# AT32UC3C1256C device description
Architecture: AVR32_UC3; Family: AVR UC3
Registers are 32-bit, read-write, reset 0x0 unless marked. A register's access mark holds for its fields unless they carry their own. Offsets are from the block's base; [hi:lo] are bit positions; {n}, {i} and the like mark numbered series; 'fields as' and 'values as' point back to an identical list.

## SAU — Secure Access Unit
Instances: SAU 0xfffe2400, SAU_HSB 0x90000000 in hsb
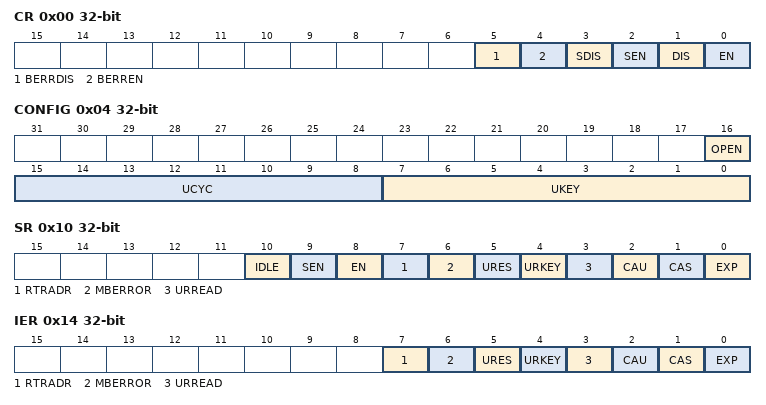
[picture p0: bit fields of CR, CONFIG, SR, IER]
0x00 CR wo reset not defined — Control Register
  [5] BERRDIS — Bus Error Response Disable
  [4] BERREN — Bus Error Response Enable
  [3] SDIS — Setup Mode Disable
  [2] SEN — Setup Mode Enable
  [1] DIS — SAU Disable
  [0] EN — SAU Enable
0x04 CONFIG wo — Configuration Register
  [16] OPEN — Open Mode Enable
  [15:8] UCYC — Unlock number of clock cycles
  [7:0] UKEY — Unlock Key
0x08 CERH — Channel Enable Register High
  [30:0] CERH
0x0C CERL — Channel Enable Register Low
0x10 SR ro — Status Register
  [10] IDLE — SAU Master Interface Idle
  [9] SEN — SAU Setup Mode Enabled
  [8] EN — SAU Enabled
  [7] RTRADR — RTR Address Error
  [6] MBERROR — Master Interface Bus Error
  [5] URES — Unlock Register Error
  [4] URKEY — Unlock Register Key Error
  [3] URREAD — Unlock Register Read
  [2] CAU — Channel Access Unsuccessful
  [1] CAS — Channel Access Successful
  [0] EXP — Channel Unlock Expired
0x14 IER wo reset not defined — Interrupt Enable Register
  [7] RTRADR — Enable Illegal RTR Address Setup Interrupt
  [6] MBERROR — Enable Master Interface Bus Error Interrupt
  [5] URES — Enable Unlock Register Error Interrupt
  [4] URKEY — Enable Unlock Register Key Error Interrupt
  [3] URREAD — Enable Unlock Register Read Interrupt
  [2] CAU — Enable Channel Access Unsuccessful Interrupt
  [1] CAS — Enable Channel Access Successful Interrupt
  [0] EXP — Enable Channel Unlock Expired Interrupt
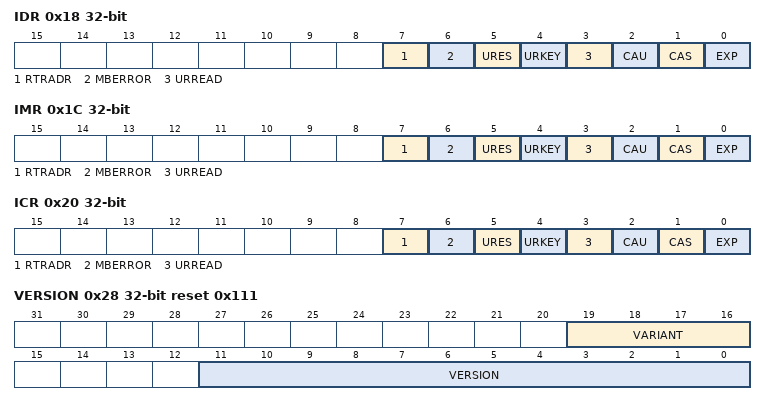
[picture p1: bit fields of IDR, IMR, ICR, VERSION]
0x18 IDR wo reset not defined — Interrupt Disable Register
  [7] RTRADR — Disable Illegal RTR Address Setup Interrupt
  [6] MBERROR — Disable Master Interface Bus Error Interrupt
  [5] URES — Disable Inlock Register Error Interrupt
  [4] URKEY — Disable Unlock Register Key Error Interrupt
  [3] URREAD — Disable Unlock Register Read Interrupt
  [2] CAU — Disable Channel Access Unsuccessful Interrupt
  [1] CAS — Disable Channel Access Successful Interrupt
  [0] EXP — Disable Channel Unlock Expired Interrupt
0x1C IMR ro — Interrupt Mask Register
  [7] RTRADR — Illegal RTR Address Setup Interrupt Mask Bit
  [6] MBERROR — Master Interface Bus Error Interrupt Mask Bit
  [5] URES — Unlock Register Error Interrupt Mask Bit
  [4] URKEY — Unlock Register Key Error Interrupt Mask Bit
  [3] URREAD — Unlock Register Read Interrupt Mask Bit
  [2] CAU — Channel Access Unsuccessful Interrupt Mask Bit
  [1] CAS — Channel Access Successful Interrupt Mask Bit
  [0] EXP — Channel Unlock Expired Interrupt Mask Bit
0x20 ICR wo reset not defined — Interrupt Clear Register
  [7] RTRADR — Clear Illegal RTR Address Setup bit
  [6] MBERROR — Clear Master Interface Bus Error bit
  [5] URES — Clear Unlock Register Error bit
  [4] URKEY — Clear Unlock Register Key Error bit
  [3] URREAD — Clear Unlock Register Read bit
  [2] CAU — Clear Channel Access Unsuccessful bit
  [1] CAS — Clear Channel Access Successful bit
  [0] EXP — Clear Channel Unlock Expired bit
0x24 PARAMETER ro reset 0x10
  [5:0] CHANNELS — SAU Parameters
0x28 VERSION ro reset 0x111
  [19:16] VARIANT — Variant number
  [11:0] VERSION — Version number

## SAU_HSB — Secure Access Unit
{0x0+4i} RTR[{i}] (i=0..62) access not given reset not defined
  [31:0] RTR — Remap Target Address for channel n
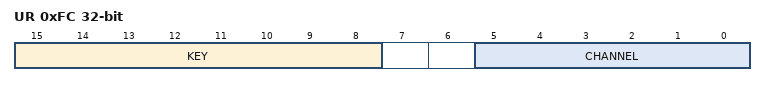
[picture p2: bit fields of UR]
0xFC UR wo reset not defined — Unlock Register
  [15:8] KEY — Unlock Key
  [5:0] CHANNEL — Channel number

## TWIM — Two-wire Master Interface
Instances: TWIM0 0xffff3800, TWIM1 0xffff3c00, TWIM2 0xfffd2c00
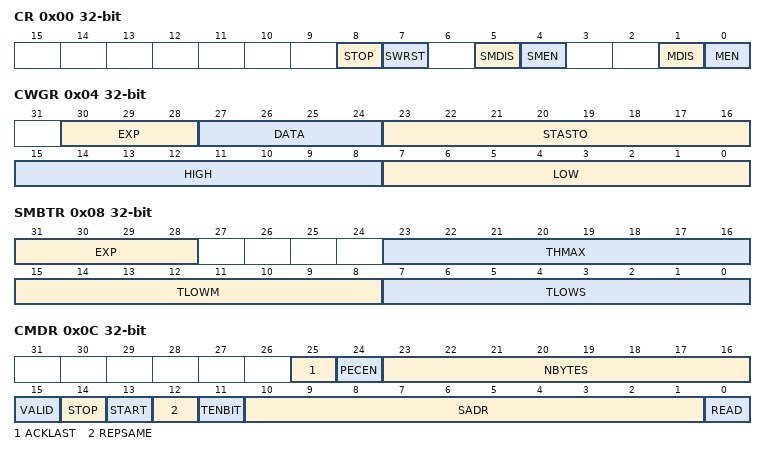
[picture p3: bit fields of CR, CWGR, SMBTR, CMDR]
0x00 CR wo — Control
  [8] STOP — Stop the current transfer
  [7] SWRST — Software Reset
  [5] SMDIS — SMBus Disable
  [4] SMEN — SMBus Enable
  [1] MDIS — Master Disable
  [0] MEN — Master Enable
0x04 CWGR — Clock Waveform Generator
  [30:28] EXP — Clock Prescaler
  [27:24] DATA — Data Setup and Hold Cycles
  [23:16] STASTO — START and STOP Cycles
  [15:8] HIGH — Clock High Cycles
  [7:0] LOW — Clock Low Cycles
0x08 SMBTR — SMBus Timing
  [31:28] EXP — SMBus Timeout Clock prescaler
  [23:16] THMAX — Clock High maximum cycles
  [15:8] TLOWM — Master Clock stretch maximum cycles
  [7:0] TLOWS — Slave Clock stretch maximum cycles
0x0C CMDR — Command
  [25] ACKLAST — ACK Last Master RX Byte
  [24] PECEN — Packet Error Checking Enable
  [23:16] NBYTES — Number of data bytes in transfer
  [15] VALID — CMDR Valid
  [14] STOP — Send STOP condition
  [13] START — Send START condition
  [12] REPSAME — Transfer is to same address as previous address
  [11] TENBIT — Ten Bit Addressing Mode
  [10:1] SADR — Slave Address
  [0] READ — Transfer Direction
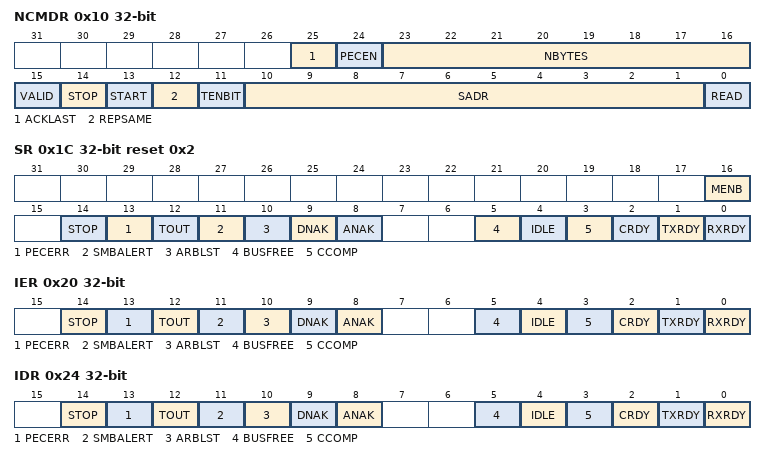
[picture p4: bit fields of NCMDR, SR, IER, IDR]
0x10 NCMDR — Next Command
  fields as CMDR
0x14 RHR ro — Receive Holding
  [7:0] RXDATA — Received Data
0x18 THR wo — Transmit Holding
  [7:0] TXDATA — Data to Transmit
0x1C SR ro reset 0x2 — Status
  [16] MENB — Master Interface Enable
  [14] STOP — Stop Request Accepted
  [13] PECERR — PEC Error
  [12] TOUT — Timeout
  [11] SMBALERT — SMBus Alert
  [10] ARBLST — Arbitration Lost
  [9] DNAK — NAK in Data Phase Received
  [8] ANAK — NAK in Address Phase Received
  [5] BUSFREE — Two-wire Bus is Free
  [4] IDLE — Master Interface is Idle
  [3] CCOMP — Command Complete
  [2] CRDY — Ready for More Commands
  [1] TXRDY — THR Data Ready
  [0] RXRDY — RHR Data Ready
0x20 IER wo — Interrupt Enable Register
  [14] STOP — Stop Request Accepted
  [13] PECERR — PEC Error
  [12] TOUT — Timeout
  [11] SMBALERT — SMBus Alert
  [10] ARBLST — Arbitration Lost
  [9] DNAK — NAK in Data Phase Received
  [8] ANAK — NAK in Address Phase Received
  [5] BUSFREE — Two-wire Bus is Free
  [4] IDLE — Master Interface is Idle
  [3] CCOMP — Command Complete
  [2] CRDY — Ready for More Commands
  [1] TXRDY — THR Data Ready
  [0] RXRDY — RHR Data Ready
0x24 IDR wo — Interrupt Disable Register
  fields as IER
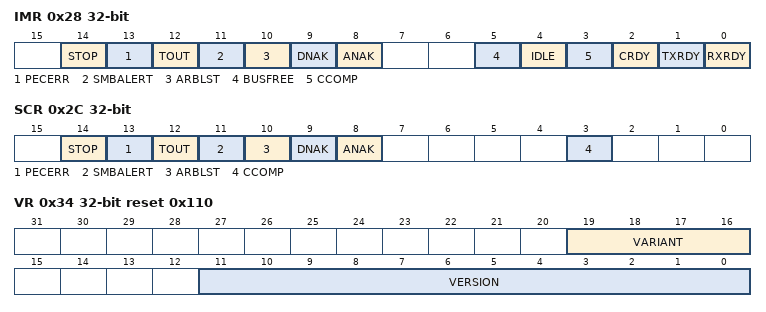
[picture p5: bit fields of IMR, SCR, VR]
0x28 IMR ro — Interrupt Mask Register
  fields as IER
0x2C SCR wo — Status Clear Register
  [14] STOP — Stop Request Accepted
  [13] PECERR — PEC Error
  [12] TOUT — Timeout
  [11] SMBALERT — SMBus Alert
  [10] ARBLST — Arbitration Lost
  [9] DNAK — NAK in Data Phase Received
  [8] ANAK — NAK in Address Phase Received
  [3] CCOMP — Command Complete
0x30 PR ro — Parameter Register
0x34 VR ro reset 0x110 — Version Register
  [19:16] VARIANT — Variant number
  [11:0] VERSION — Version number
